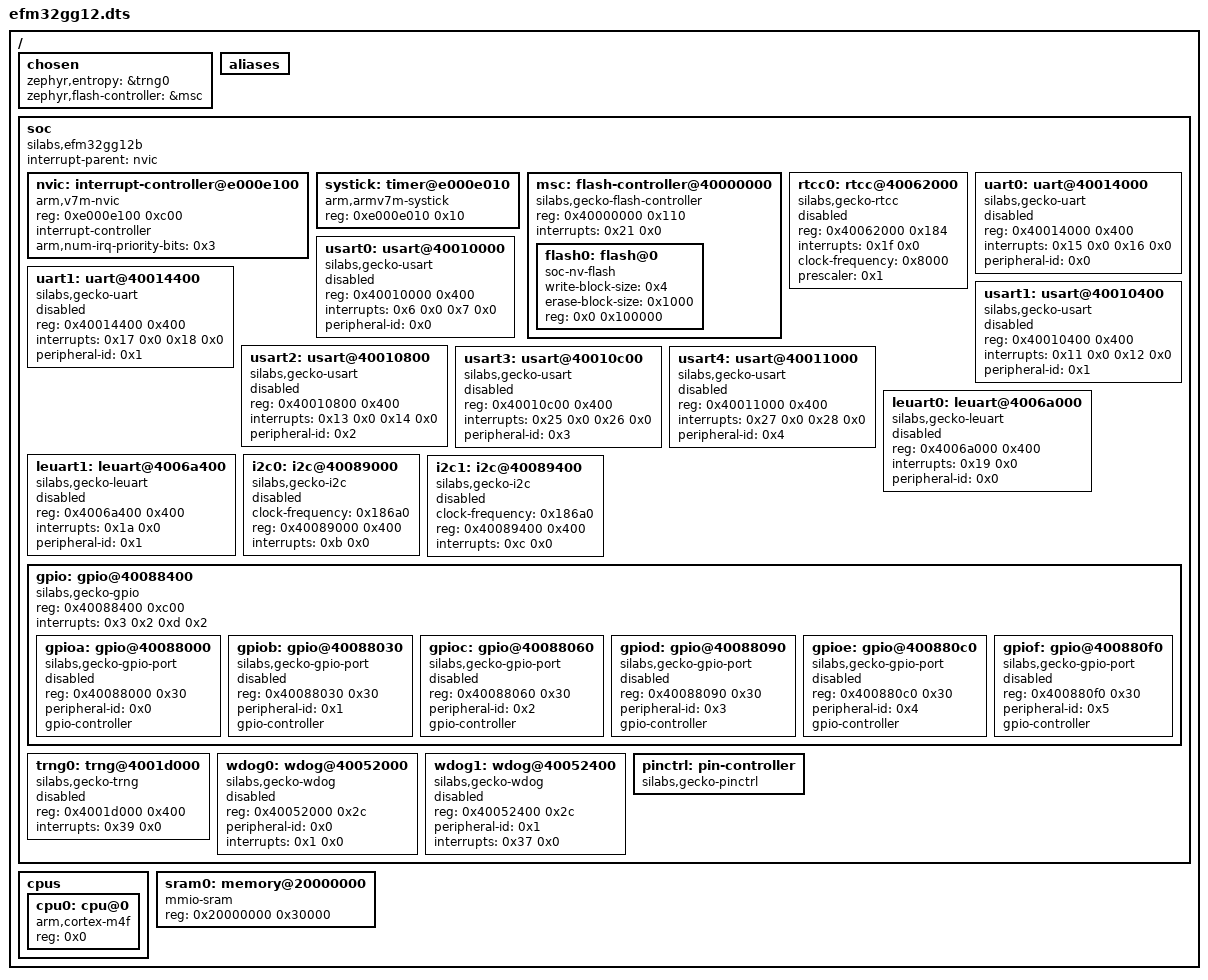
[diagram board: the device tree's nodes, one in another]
/dts-v1/;

/ {
	#address-cells = < 0x1 >;
	#size-cells = < 0x1 >;
	chosen {
		zephyr,entropy = &trng0;
		zephyr,flash-controller = &msc;
	};
	aliases {
	};
	soc {
		#address-cells = < 0x1 >;
		#size-cells = < 0x1 >;
		compatible = "silabs,efm32gg12b", "silabs,efm32gg12", "silabs,efm32", "simple-bus";
		interrupt-parent = < &nvic >;
		ranges;
		nvic: interrupt-controller@e000e100 {
			#address-cells = < 0x1 >;
			compatible = "arm,v7m-nvic";
			reg = < 0xe000e100 0xc00 >;
			interrupt-controller;
			#interrupt-cells = < 0x2 >;
			arm,num-irq-priority-bits = < 0x3 >;
			phandle = < 0x1 >;
		};
		systick: timer@e000e010 {
			compatible = "arm,armv7m-systick";
			reg = < 0xe000e010 0x10 >;
		};
		msc: flash-controller@40000000 {
			compatible = "silabs,gecko-flash-controller";
			reg = < 0x40000000 0x110 >;
			interrupts = < 0x21 0x0 >;
			#address-cells = < 0x1 >;
			#size-cells = < 0x1 >;
			flash0: flash@0 {
				compatible = "soc-nv-flash";
				write-block-size = < 0x4 >;
				erase-block-size = < 0x1000 >;
				reg = < 0x0 0x100000 >;
			};
		};
		rtcc0: rtcc@40062000 {
			compatible = "silabs,gecko-rtcc";
			reg = < 0x40062000 0x184 >;
			interrupts = < 0x1f 0x0 >;
			clock-frequency = < 0x8000 >;
			prescaler = < 0x1 >;
			status = "disabled";
		};
		uart0: uart@40014000 {
			compatible = "silabs,gecko-uart";
			reg = < 0x40014000 0x400 >;
			interrupts = < 0x15 0x0 0x16 0x0 >;
			interrupt-names = "rx", "tx";
			peripheral-id = < 0x0 >;
			status = "disabled";
		};
		uart1: uart@40014400 {
			compatible = "silabs,gecko-uart";
			reg = < 0x40014400 0x400 >;
			interrupts = < 0x17 0x0 0x18 0x0 >;
			interrupt-names = "rx", "tx";
			peripheral-id = < 0x1 >;
			status = "disabled";
		};
		usart0: usart@40010000 {
			compatible = "silabs,gecko-usart";
			reg = < 0x40010000 0x400 >;
			interrupts = < 0x6 0x0 0x7 0x0 >;
			interrupt-names = "rx", "tx";
			peripheral-id = < 0x0 >;
			status = "disabled";
		};
		usart1: usart@40010400 {
			compatible = "silabs,gecko-usart";
			reg = < 0x40010400 0x400 >;
			interrupts = < 0x11 0x0 0x12 0x0 >;
			interrupt-names = "rx", "tx";
			peripheral-id = < 0x1 >;
			status = "disabled";
		};
		usart2: usart@40010800 {
			compatible = "silabs,gecko-usart";
			reg = < 0x40010800 0x400 >;
			interrupts = < 0x13 0x0 0x14 0x0 >;
			interrupt-names = "rx", "tx";
			peripheral-id = < 0x2 >;
			status = "disabled";
		};
		usart3: usart@40010c00 {
			compatible = "silabs,gecko-usart";
			reg = < 0x40010c00 0x400 >;
			interrupts = < 0x25 0x0 0x26 0x0 >;
			interrupt-names = "rx", "tx";
			peripheral-id = < 0x3 >;
			status = "disabled";
		};
		usart4: usart@40011000 {
			compatible = "silabs,gecko-usart";
			reg = < 0x40011000 0x400 >;
			interrupts = < 0x27 0x0 0x28 0x0 >;
			interrupt-names = "rx", "tx";
			peripheral-id = < 0x4 >;
			status = "disabled";
		};
		leuart0: leuart@4006a000 {
			compatible = "silabs,gecko-leuart";
			reg = < 0x4006a000 0x400 >;
			interrupts = < 0x19 0x0 >;
			peripheral-id = < 0x0 >;
			status = "disabled";
		};
		leuart1: leuart@4006a400 {
			compatible = "silabs,gecko-leuart";
			reg = < 0x4006a400 0x400 >;
			interrupts = < 0x1a 0x0 >;
			peripheral-id = < 0x1 >;
			status = "disabled";
		};
		i2c0: i2c@40089000 {
			compatible = "silabs,gecko-i2c";
			clock-frequency = < 0x186a0 >;
			#address-cells = < 0x1 >;
			#size-cells = < 0x0 >;
			reg = < 0x40089000 0x400 >;
			interrupts = < 0xb 0x0 >;
			status = "disabled";
		};
		i2c1: i2c@40089400 {
			compatible = "silabs,gecko-i2c";
			clock-frequency = < 0x186a0 >;
			#address-cells = < 0x1 >;
			#size-cells = < 0x0 >;
			reg = < 0x40089400 0x400 >;
			interrupts = < 0xc 0x0 >;
			status = "disabled";
		};
		gpio: gpio@40088400 {
			compatible = "silabs,gecko-gpio";
			reg = < 0x40088400 0xc00 >;
			interrupts = < 0x3 0x2 0xd 0x2 >;
			interrupt-names = "GPIO_EVEN", "GPIO_ODD";
			ranges;
			#address-cells = < 0x1 >;
			#size-cells = < 0x1 >;
			gpioa: gpio@40088000 {
				compatible = "silabs,gecko-gpio-port";
				reg = < 0x40088000 0x30 >;
				peripheral-id = < 0x0 >;
				gpio-controller;
				#gpio-cells = < 0x2 >;
				status = "disabled";
			};
			gpiob: gpio@40088030 {
				compatible = "silabs,gecko-gpio-port";
				reg = < 0x40088030 0x30 >;
				peripheral-id = < 0x1 >;
				gpio-controller;
				#gpio-cells = < 0x2 >;
				status = "disabled";
			};
			gpioc: gpio@40088060 {
				compatible = "silabs,gecko-gpio-port";
				reg = < 0x40088060 0x30 >;
				peripheral-id = < 0x2 >;
				gpio-controller;
				#gpio-cells = < 0x2 >;
				status = "disabled";
			};
			gpiod: gpio@40088090 {
				compatible = "silabs,gecko-gpio-port";
				reg = < 0x40088090 0x30 >;
				peripheral-id = < 0x3 >;
				gpio-controller;
				#gpio-cells = < 0x2 >;
				status = "disabled";
			};
			gpioe: gpio@400880c0 {
				compatible = "silabs,gecko-gpio-port";
				reg = < 0x400880c0 0x30 >;
				peripheral-id = < 0x4 >;
				gpio-controller;
				#gpio-cells = < 0x2 >;
				status = "disabled";
			};
			gpiof: gpio@400880f0 {
				compatible = "silabs,gecko-gpio-port";
				reg = < 0x400880f0 0x30 >;
				peripheral-id = < 0x5 >;
				gpio-controller;
				#gpio-cells = < 0x2 >;
				status = "disabled";
			};
		};
		trng0: trng@4001d000 {
			compatible = "silabs,gecko-trng";
			reg = < 0x4001d000 0x400 >;
			interrupts = < 0x39 0x0 >;
			status = "disabled";
		};
		wdog0: wdog@40052000 {
			compatible = "silabs,gecko-wdog";
			reg = < 0x40052000 0x2c >;
			peripheral-id = < 0x0 >;
			interrupts = < 0x1 0x0 >;
			status = "disabled";
		};
		wdog1: wdog@40052400 {
			compatible = "silabs,gecko-wdog";
			reg = < 0x40052400 0x2c >;
			peripheral-id = < 0x1 >;
			interrupts = < 0x37 0x0 >;
			status = "disabled";
		};
		pinctrl: pin-controller {
			compatible = "silabs,gecko-pinctrl";
		};
	};
	cpus {
		#address-cells = < 0x1 >;
		#size-cells = < 0x0 >;
		cpu0: cpu@0 {
			compatible = "arm,cortex-m4f";
			reg = < 0x0 >;
		};
	};
	sram0: memory@20000000 {
		compatible = "mmio-sram";
		reg = < 0x20000000 0x30000 >;
	};
};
